# CY8C4xxx register map
File version: 0.1
Registers are 8-bit, read-write, no defined reset value unless marked. A register's access mark holds for its fields unless they carry their own. Offsets are from the block's base; [hi:lo] are bit positions; {n}, {i} and the like mark numbered series; 'fields as' and 'values as' point back to an identical list.

## SFLASH — Supervisory Flash Area (Cypress Trim & Wounding Info)
Base 0x0FFFF000
{0x0+i} PROT_ROW{i:02} (i=0..63) — Per Page Write Protection
  [7:0] DATA8 — Protection Data (1b per page)
0x7F PROT_PROTECTION — Protection Level
  [1:0] PROT_LEVEL — Current Protection Mode - note that encoding is different from CPUSS_PROTECTION !!
    1=VIRGIN; 0=OPEN; 2=PROTECTED; 3=KILL
{0x100+4i} AV_PAIRS_32B{i:02} 32-bit (i=0..15) — 32b Addr/Value pair Section
  [31:0] DATA32 — Address or Value Word
0x140 CPUSS_WOUNDING 32-bit
  [31:0] DATA32 — Data to use for register
0x144 SILICON_ID 32-bit
  [15:0] ID
0x148 CPUSS_PRIV_RAM 32-bit — RAM Privileged Limit
  [31:0] DATA32 — Data to use for register
0x14C CPUSS_PRIV_FLASH 32-bit — Flash Privileged Limit
  [31:0] DATA32 — Data to use for register
0x150 HIB_KEY_DELAY 16-bit — Hibernate wakeup value for PWR_KEY_DELAY
  [9:0] WAKEUP_HOLDOFF — Delay (in 12MHz IMO clock cycles) to wait for references to settle on wakeup from hibernate/deepsleep. PBOD is ignored and system does not resume until this delay expires. Note that the same delay on POR is hard-coded.
0x152 DPSLP_KEY_DELAY 16-bit — DeepSleep wakeup value for PWR_KEY_DELAY
  fields as HIB_KEY_DELAY
0x154 SWD_CONFIG — SWD pinout selector (not present in TSG4/TSG5-M)
  [0] SWD_SELECT — 0: Use Primary SWD location?1: Use Alternate SWD location
0x158 SWD_LISTEN 32-bit — Listen Window Length
  [31:0] CYCLES — Number of clock cycles
0x15C FLASH_START 32-bit — Flash Image Start Address
  [31:0] ADDRESS — Start Address
0x160 CSD_TRIM1_HVIDAC — CSD Trim Data for HVIDAC operation
  [7:0] TRIM8 — Trim data
0x161 CSD_TRIM2_HVIDAC — CSD Trim Data for HVIDAC operation
  [7:0] TRIM8 — Trim data
0x162 CSD_TRIM1_CSD — CSD Trim Data for (normal) CSD operation
  [7:0] TRIM8 — Trim data
0x163 CSD_TRIM2_CSD — CSD Trim Data for (normal) CSD operation
  [7:0] TRIM8 — Trim data
0x164 SAR_TEMP_MULTIPLIER 16-bit — SAR Temperature Sensor Multiplication Factor
  [15:0] TEMP_MULTIPLIER — Multiplier value for SAR temperature sensor in fixed point 0.16 format. Note: this field exists in products that contain SAR (m0s8sar) only.
0x166 SAR_TEMP_OFFSET 16-bit — SAR Temperature Sensor Offset
  [15:0] TEMP_OFFSET — Offset value for SAR temperature sensor in fixed point 10.6 format. Note: this field exists in products that contain SAR (m0s8sar) only.
0x169 SKIP_CHECKSUM — Checksum Skip Option Register
  [7:0] SKIP — 0: Perform checksum check (see CHECKSUM fueld below)?1: Skip checksum check?>1: Undefined - do not use
{0x170+i} PROT_VIRGINKEY{i} (i=0..7) — Virgin Protection Mode Key
  [7:0] KEY8 — Key Byte
{0x178+i} DIE_LOT{i} (i=0..2) — Lot Number (3 bytes)
  [7:0] LOT — Lot Number Byte
0x17B DIE_WAFER — Wafer Number
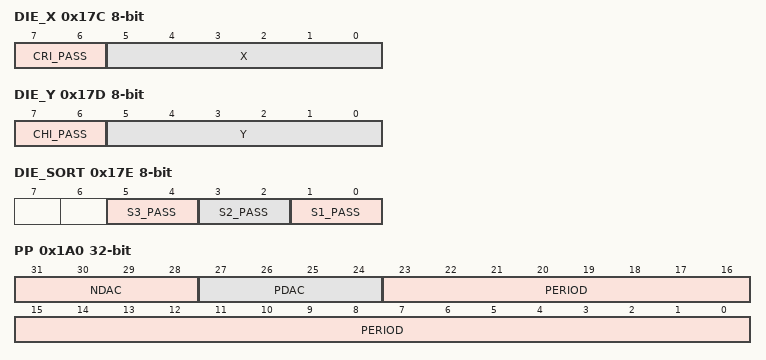
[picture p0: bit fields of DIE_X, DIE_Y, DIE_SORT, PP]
0x17C DIE_X — X Position on Wafer, CRI Pass/Fail Bin
  [7:6] CRI_PASS — CRI Pass Bin (1-3) or 0 (Fail Bin)
  [5:0] X — X Position
0x17D DIE_Y — Y Position on Wafer, CHI Pass/Fail Bin
  [7:6] CHI_PASS — CHI Pass Bin (1-3) or 0 (Fail Bin)
  [5:0] Y — Y Position
0x17E DIE_SORT — Sort1/2/3 Pass/Fail Bin
  [5:4] S3_PASS — SORT3 Pass Bin (1-3) or 0 (Fail Bin)
  [3:2] S2_PASS — SORT2 Pass Bin (1-3) or 0 (Fail Bin)
  [1:0] S1_PASS — SORT1 Pass Bin (1-3) or 0 (Fail Bin)
0x17F DIE_MINOR — Minor Revision Number
  [7:0] MINOR — Minor revision number
{0x180+i} PE_TE_DATA{i:02} (i=0..31) — PE/TE Data
  [7:0] DATA8
0x1A0 PP 32-bit — Preprogram Settings
  [31:28] NDAC — NDAC input. Each increment in NDAC causes an increase of ~0.10V in VNEG
  [27:24] PDAC — PDAC input. Each increment in PDAC causes an increase of ~0.10V in VPOS
  [23:0] PERIOD — Period of timer (in units of 36 MHz IMO clock periods).
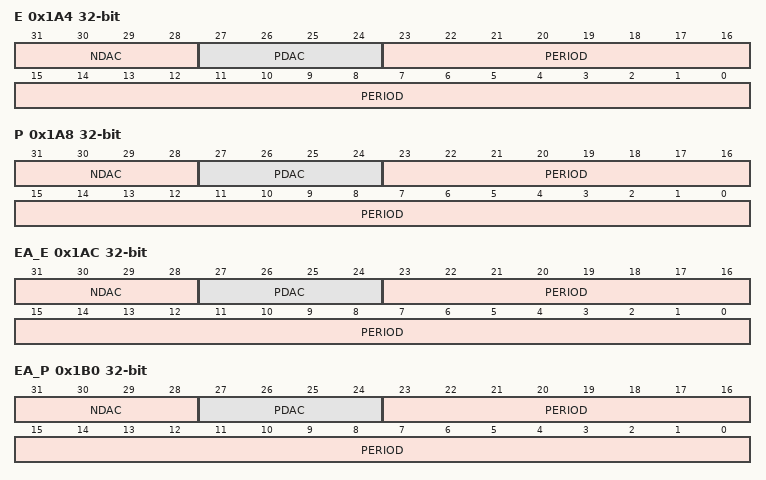
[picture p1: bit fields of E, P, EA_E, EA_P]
0x1A4 E 32-bit — Erase Settings
  fields as PP
0x1A8 P 32-bit — Program Settings
  fields as PP
0x1AC EA_E 32-bit — Erase All - Erase Settings
  fields as PP
0x1B0 EA_P 32-bit — Erase All - Program Settings
  fields as PP
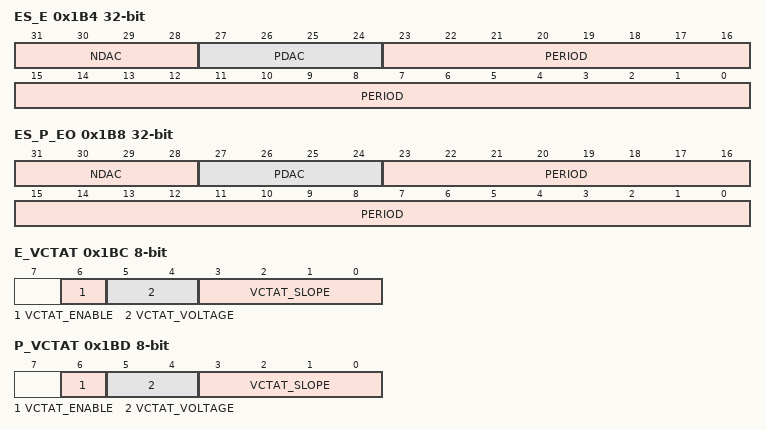
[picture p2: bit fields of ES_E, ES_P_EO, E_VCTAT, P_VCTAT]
0x1B4 ES_E 32-bit — Erase Sector - Erase Settings
  fields as PP
0x1B8 ES_P_EO 32-bit — Erase Sector - Program EO Settings
  fields as PP
0x1BC E_VCTAT — Bandgap Trim Register
  [6] VCTAT_ENABLE — Enable VCTAT block
  [5:4] VCTAT_VOLTAGE — Output voltage absolute trim
  [3:0] VCTAT_SLOPE — Output slope setting controls. The slope of the voltage with temperature varies from ~0% to ~15% from the value at 55C over the temperature range -40C to 150C based on control signal settings 0 to 15
0x1BD P_VCTAT — Bandgap Trim Register
  fields as E_VCTAT
0x1BE MARGIN — Margin DAC Control Register
  [7:0] MDAC — Margin DAC input. Each increment increases the VMARG by?~15.6mV
0x1BF SPCIF_TRIM1 — BDAC control register
  [3:0] BDAC — BDAC flash input. Trims flash bitline program inhibit voltage. Each increment causes an increase of 0.12V (0V-1.8V)
{0x1C0+3i} IMO_MAXF{i} (i=0..3) — Max frequency for trim pair
  [5:0] MAXFREQ — Max frequency (3..48) at which IMO_ABS/TMPCO3 is valid (range is IMO_MAXF2+1 .. IMO_MAXF3).
{0x1C1+3i} IMO_ABS{i} (i=0..3) — Value for PWR_BG_TRIM4 (ICTAT trim for IMO current reference).
  [5:0] ABS_TRIM_IMO — IMO-irefgen output current magnitude trim
{0x1C2+3i} IMO_TMPCO{i} (i=0..3) — Value for PWR_BG_TRIM5 (ICTAT tempco for IMO current reference).
  [5:0] TMPCO_TRIM_IMO — IMO-irefgen output current temperature co-efficient trim
0x1CC IMO_ABS4 — Value for PWR_BG_TRIM4 (ICTAT trim for IMO current reference).
  [5:0] ABS_TRIM_IMO — IMO-irefgen output current magnitude trim
0x1CD IMO_TMPCO4 — Value for PWR_BG_TRIM5 (ICTAT tempco for IMO current reference).
  fields as IMO_TMPCO0
{0x1D0+i} IMO_TRIM{i:02} (i=0..45) — IMO Trim Register
  [7:0] OFFSET — Frequency trim bits. These bits are determined at manufacturing time for each FREQ setting (IMO_TRIM2) and stored in SFLASH.
0x1FE CHECKSUM 16-bit — Boot Checksum
  [15:0] CHECKSUM — Checksum of fixed data checked during boot. This checksum covers all of rows 1,2,3 of macro 0 + row 3 of macro 1 (except this checksum, and row 3 of macro 1 only if it exists).
